# PIC16LF1613 register map
Vendor: Microchip
Architecture 16Exxx. Special function registers and configuration words.
Registers are 8-bit, read-write, reset 0x0 unless marked. A register's access mark holds for its fields unless they carry their own. Addresses are absolute, and some are shared; only a register's first bit layout is shown; lines under a group give offsets from that group; [hi:lo] are bit positions; {n}, {i} and the like mark numbered series; 'fields as' and 'values as' point back to an identical list; <NAME> marks a mode.

## Further device data
pins=1: Vdd; 2: RA5/CLKIN/SMT1WIN/T1CKI/T2IN/CCP2/IOCA5; 3: RA4/CLKOUT/SMT1SIG/AN3/T1G/IOCA4; 4: RA3/SMT2WIN/T1G/T6IN/IOCA3/VPP/nMCLR/MCLR; 5: RC5/CWG1A/CCP1/IOCC5; 6: RC4/CWG1B/C2OUT/IOCC4; 7: RC3/AN7/C1IN3-/C2IN3-/CWG1C/CCP2/IOCC3; 8: RC2/AN6/C1IN2-/C2IN2-/CWG1D/IOCC2; 9: RC1/SMT2SIG/AN5/C1IN1-/C2IN1-/T4IN/IOCC1; 10: RC0/AN4/C2IN+/IOCC0; 11: RA2/ZCD1IN/AN2/CWG1IN/C1OUT/T0CKI/INT/IOCA2; 12: RA1/ZCD1OUT/VREF+DAC/VREF+ADC/AN1/C1IN0-/C2IN0-/IOCA1; 13: RA0/DAC1OUT/AN0/C1IN+/IOCA0; 14: Vss

## tmr
0x1A T2TMR — 8-bit period timer
  [7:0] TMR2
0x1B T2PR reset 0xFF
  [7:0] PR2
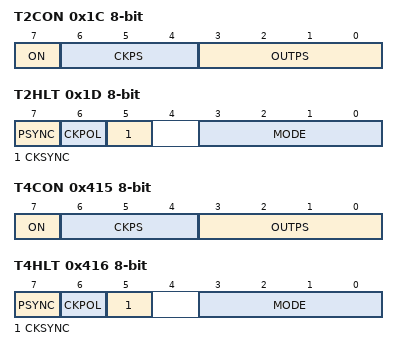
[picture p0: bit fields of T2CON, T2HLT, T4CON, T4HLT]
0x1C T2CON reset not defined — (power-on value 0xxxxxxx)
  [7] ON, [6:4] CKPS, [3:0] OUTPS
0x1D T2HLT reset not defined — (power-on value 00x-0000)
  [7] PSYNC, [6] CKPOL, [5] CKSYNC, [3:0] MODE
0x1E T2CLKCON
  [2:0] T2CS
0x1F T2RST
  [3:0] RSEL
0x413 T4TMR — 8-bit period timer
  [7:0] TMR4
0x414 T4PR reset 0xFF
  [7:0] PR4
0x415 T4CON reset not defined — (power-on value 0xxxxxxx)
  [7] ON, [6:4] CKPS, [3:0] OUTPS
0x416 T4HLT reset not defined — (power-on value 00x-0000)
  [7] PSYNC, [6] CKPOL, [5] CKSYNC, [3:0] MODE
0x417 T4CLKCON
  [2:0] T4CS
0x418 T4RST
  [3:0] RSEL
0x41A T6TMR — 8-bit period timer
  [7:0] TMR6
0x41B T6PR reset 0xFF
  [7:0] PR6
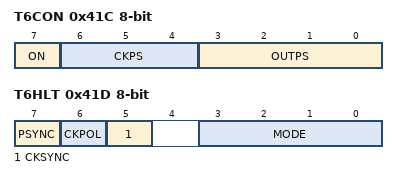
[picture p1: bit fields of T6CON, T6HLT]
0x41C T6CON reset not defined — (power-on value 0xxxxxxx)
  [7] ON, [6:4] CKPS, [3:0] OUTPS
0x41D T6HLT reset not defined — (power-on value 00x-0000)
  [7] PSYNC, [6] CKPOL, [5] CKSYNC, [3:0] MODE
0x41E T6CLKCON
  [2:0] T6CS
0x41F T6RST
  [3:0] RSEL

## ccp
0x291 CCPR1L reset not defined — (power-on value xxxxxxxx)
  [7:0] RL
0x292 CCPR1H reset not defined — (power-on value xxxxxxxx)
  [7:0] RH
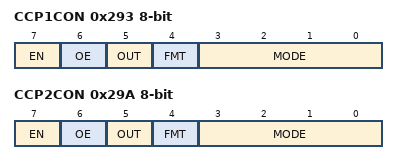
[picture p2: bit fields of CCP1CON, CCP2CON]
0x293 CCP1CON
  [7] EN, [6] OE, [5] OUT ro, [4] FMT, [3:0] MODE
0x294 CCP1CAP
  [1:0] CTS
0x298 CCPR2L reset not defined — (power-on value xxxxxxxx)
  [7:0] RL
0x299 CCPR2H reset not defined — (power-on value xxxxxxxx)
  [7:0] RH
0x29A CCP2CON
  [7] EN, [6] OE, [5] OUT ro, [4] FMT, [3:0] MODE
0x29B CCP2CAP
  [1:0] CTS

## wg_cwg
0x691 CWG1DBR
  [5:0] DBR
0x692 CWG1DBF
  [5:0] DBF
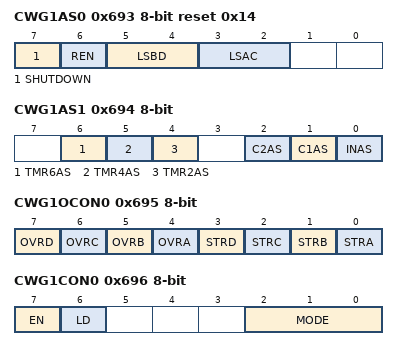
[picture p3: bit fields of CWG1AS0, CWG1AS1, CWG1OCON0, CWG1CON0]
0x693 CWG1AS0 reset 0x14
  [7] SHUTDOWN, [6] REN, [5:4] LSBD, [3:2] LSAC
0x694 CWG1AS1
  [6] TMR6AS, [5] TMR4AS, [4] TMR2AS, [2] C2AS, [1] C1AS, [0] INAS
0x695 CWG1OCON0
  [7] OVRD, [6] OVRC, [5] OVRB, [4] OVRA, [3] STRD, [2] STRC, [1] STRB, [0] STRA
0x696 CWG1CON0
  [7] EN, [6] LD, [2:0] MODE
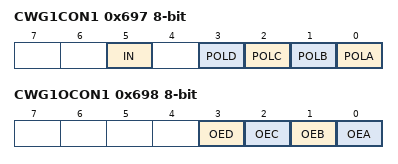
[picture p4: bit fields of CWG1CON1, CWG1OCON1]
0x697 CWG1CON1
  [5] IN ro, [3] POLD, [2] POLC, [1] POLB, [0] POLA
0x698 CWG1OCON1
  [3] OED, [2] OEC, [1] OEB, [0] OEA
0x699 CWG1CLKCON
  [0] CS
0x69A CWG1ISM
  [2:0] IS

## wdt_windowed
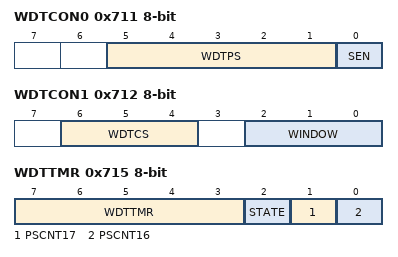
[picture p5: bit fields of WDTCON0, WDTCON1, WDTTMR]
0x711 WDTCON0 reset not defined — (power-on value --qqqqq0)
  [5:1] WDTPS, [0] SEN
0x712 WDTCON1 reset not defined — (power-on value -qqq-qqq)
  [6:4] WDTCS, [2:0] WINDOW
0x713 WDTPSL ro
  [7:0] PSCNT
0x714 WDTPSH ro
  [7:0] PSCNT
0x715 WDTTMR ro reset not defined — (power-on value xxxxx000)
  [7:3] WDTTMR, [2] STATE, [1] PSCNT17, [0] PSCNT16

## dma_nvm
0x718 SCANLADRL
  [7:0] LADR
0x719 SCANLADRH
  [7:0] LADR
0x71A SCANHADRL reset 0xFF
  [7:0] HADR
0x71B SCANHADRH reset 0xFF
  [7:0] HADR
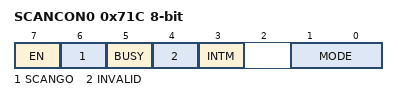
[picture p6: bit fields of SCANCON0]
0x71C SCANCON0
  [7] EN, [6] SCANGO, [5] BUSY ro, [4] INVALID ro, [3] INTM, [1:0] MODE
0x71D SCANTRIG
  [1:0] TSEL
